VERSION ""

NS_ :

BS_:

BU_: PTECU FECU RECO MECU PC_Tool

BA_DEF_ "VFrameFormat" ENUM "StandardCAN","StandardCAN_FD";
BA_DEF_ BO_ "CAN_FD_BRS" ENUM "0","1";
VAL_ 1808 Engine_State 0 "Desligado" 1 "Partida" 2 "Funcionando" 3 "Falha";

// --------------------------- MECU ---------------------------
BO_ 272 MECU_ReqCuttingBrake: 1 MECU
 SG_ CuttingBreakAtivado : 0|1@1+ (1,0) [0|1] "bool" RECO

BO_ 273 MECU_Status_Seguranca: 1 MECU
 SG_ ChaveGeral_Ativada : 0|1@1+ (1,0) [0|1] "bool" PTECU,FECU,RECO,PC_Tool
 SG_ FarolLigado : 1|1@1+ (1,0) [0|1] "bool" PTECU,FECU,RECO,PC_Tool

BO_ 1856 MECU_Diag_Response: 32 MECU
 SG_ FW_Major_MECU : 0|8@1+ (1,0) [0|255] "" PC_Tool
 SG_ FW_Minor_MECU : 8|8@1+ (1,0) [0|255] "" PC_Tool
 SG_ FW_Patch_MECU : 16|8@1+ (1,0) [0|255] "" PC_Tool
 SG_ Uptime_MECU : 24|32@1+ (1,0) [0|4294967295] "s" PC_Tool

// --------------------------- PTECU ---------------------------
BO_ 32 PTECU_Dados_Motor: 4 PTECU
 SG_ RPM : 0|16@1+ (1,0) [0|6000] "rpm" MECU
 SG_ Vel_Eixo_Traseiro : 16|16@1+ (0.1,0) [0|120] "km/h" MECU

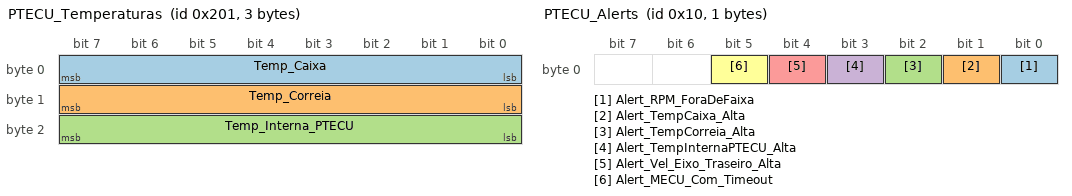
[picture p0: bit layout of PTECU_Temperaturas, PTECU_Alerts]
BO_ 513 PTECU_Temperaturas: 3 PTECU
 SG_ Temp_Caixa : 0|8@1- (1,-40) [-40|500] "C" MECU
 SG_ Temp_Correia : 8|8@1- (1,-40) [-40|500] "C" MECU
 SG_ Temp_Interna_PTECU : 16|8@1- (1,-40) [-40|125] "C" MECU

BO_ 528 PTECU_Sensores_CVT: 4 PTECU
 SG_ Lum_Entrada_Ar_CVT : 0|16@1+ (1,0) [0|65535] "count" MECU
 SG_ Lum_Dia : 16|16@1+ (1,0) [0|65535] "count" MECU

BO_ 529 PTECU_Status_Transmissao: 1 PTECU
 SG_ MarchaRe_Ativada : 0|1@1+ (1,0) [0|1] "bool" MECU,RECO

BO_ 16 PTECU_Alerts: 1 PTECU
 SG_ Alert_RPM_ForaDeFaixa : 0|1@1+ (1,0) [0|1] "bool" MECU
 SG_ Alert_TempCaixa_Alta : 1|1@1+ (1,0) [0|1] "bool" MECU
 SG_ Alert_TempCorreia_Alta : 2|1@1+ (1,0) [0|1] "bool" MECU
 SG_ Alert_TempInternaPTECU_Alta : 3|1@1+ (1,0) [0|1] "bool" MECU
 SG_ Alert_Vel_Eixo_Traseiro_Alta : 4|1@1+ (1,0) [0|1] "bool" MECU
 SG_ Alert_MECU_Com_Timeout : 5|1@1+ (1,0) [0|1] "bool" MECU

BO_ 1808 PTECU_Diag_Response: 32 PTECU
 SG_ FW_Major : 0|8@1+ (1,0) [0|255] "" PC_Tool
 SG_ FW_Minor : 8|8@1+ (1,0) [0|255] "" PC_Tool
 SG_ FW_Patch : 16|8@1+ (1,0) [0|255] "" PC_Tool
 SG_ Uptime_PTECU : 24|32@1+ (1,0) [0|4294967295] "s" PC_Tool
 SG_ Raw_ADC_Temp_Caixa : 56|16@1+ (1,0) [0|65535] "counts" PC_Tool
 SG_ Raw_ADC_Temp_Correia : 72|16@1+ (1,0) [0|65535] "counts" PC_Tool
 SG_ Engine_State : 88|8@1+ (1,0) [0|10] "" PC_Tool

// --------------------------- FECU ---------------------------
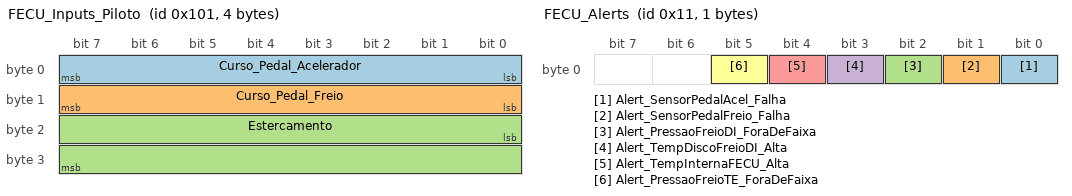
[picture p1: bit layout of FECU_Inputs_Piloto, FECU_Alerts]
BO_ 257 FECU_Inputs_Piloto: 4 FECU
 SG_ Curso_Pedal_Acelerador : 0|8@1+ (0.5,0) [0|100] "%" MECU,PTECU,RECO
 SG_ Curso_Pedal_Freio : 8|8@1+ (0.5,0) [0|100] "%" MECU
 SG_ Estercamento : 16|16@1- (0.1,0) [-90|90] "deg" MECU

BO_ 258 FECU_Dinamica_Veiculo: 16 FECU
 SG_ Vel_Semieixo_DE : 0|16@1+ (0.1,0) [0|120] "km/h" MECU
 SG_ Vel_Semieixo_DD : 16|16@1+ (0.1,0) [0|120] "km/h" MECU
 SG_ Accel_X : 32|16@1- (0.001,0) [-8|8] "g" MECU
 SG_ Accel_Y : 48|16@1- (0.001,0) [-8|8] "g" MECU
 SG_ Vel_Semieixo_TE : 64|16@1+ (0.1,0) [0|120] "km/h" MECU

BO_ 544 FECU_Sistema_Freio_Diant: 2 FECU
 SG_ Pressao_Freio_DI : 0|8@1+ (1,0) [0|100] "bar" MECU
 SG_ Temp_Disco_Freio_DI : 8|8@1- (1,-40) [-40|500] "C" MECU

BO_ 545 FECU_Sistema_Freio_Tras: 2 FECU
 SG_ Pressao_Freio_TE : 0|8@1+ (1,0) [0|100] "bar" MECU
 SG_ Temp_Disco_Freio_TE : 8|8@1- (1,-40) [-40|500] "C" MECU

BO_ 1056 FECU_Status: 1 FECU
 SG_ Temp_Interna_FECU : 0|8@1- (1,-40) [-40|125] "C" MECU

BO_ 17 FECU_Alerts: 1 FECU
 SG_ Alert_SensorPedalAcel_Falha : 0|1@1+ (1,0) [0|1] "bool" MECU
 SG_ Alert_SensorPedalFreio_Falha : 1|1@1+ (1,0) [0|1] "bool" MECU
 SG_ Alert_PressaoFreioDI_ForaDeFaixa : 2|1@1+ (1,0) [0|1] "bool" MECU
 SG_ Alert_TempDiscoFreioDI_Alta : 3|1@1+ (1,0) [0|1] "bool" MECU
 SG_ Alert_TempInternaFECU_Alta : 4|1@1+ (1,0) [0|1] "bool" MECU
 SG_ Alert_PressaoFreioTE_ForaDeFaixa : 5|1@1+ (1,0) [0|1] "bool" MECU

BO_ 1824 FECU_Diag_Response: 32 FECU
 SG_ FW_Major_FECU : 0|8@1+ (1,0) [0|255] "" PC_Tool
 SG_ FW_Minor_FECU : 8|8@1+ (1,0) [0|255] "" PC_Tool
 SG_ FW_Patch_FECU : 16|8@1+ (1,0) [0|255] "" PC_Tool
 SG_ Uptime_FECU : 24|32@1+ (1,0) [0|4294967295] "s" PC_Tool
 SG_ Raw_ADC_Pedal_Acel : 56|16@1+ (1,0) [0|65535] "counts" PC_Tool
 SG_ Raw_ADC_Pedal_Freio : 72|16@1+ (1,0) [0|65535] "counts" PC_Tool
 SG_ Raw_ADC_Estercamento : 88|16@1+ (1,0) [0|65535] "counts" PC_Tool

// --------------------------- RECO ---------------------------
BO_ 514 RECO_Status: 12 RECO
 SG_ Tensao_Bateria : 0|16@1+ (0.01,0) [8|15] "V" MECU
 SG_ Temp_Bateria : 16|8@1- (1,-40) [-40|100] "C" MECU
 SG_ Temp_Disco_Freio_Tras : 24|8@1- (1,-40) [-40|500] "C" MECU
 SG_ Temp_Interna_RECO : 32|8@1- (1,-40) [-40|125] "C" MECU

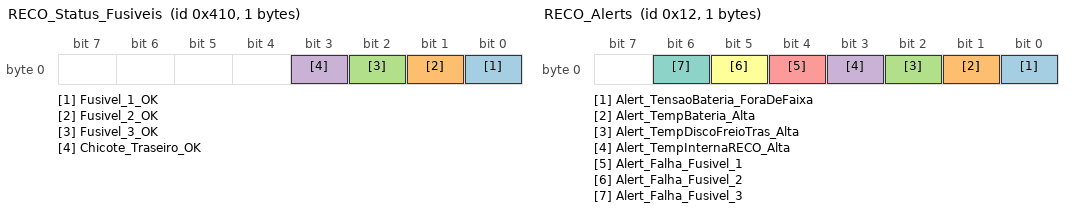
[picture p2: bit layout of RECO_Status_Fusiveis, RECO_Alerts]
BO_ 1040 RECO_Status_Fusiveis: 1 RECO
 SG_ Fusivel_1_OK : 0|1@1+ (1,0) [0|1] "bool" MECU
 SG_ Fusivel_2_OK : 1|1@1+ (1,0) [0|1] "bool" MECU
 SG_ Fusivel_3_OK : 2|1@1+ (1,0) [0|1] "bool" MECU
 SG_ Chicote_Traseiro_OK : 3|1@1+ (1,0) [0|1] "bool" MECU

BO_ 18 RECO_Alerts: 1 RECO
 SG_ Alert_TensaoBateria_ForaDeFaixa : 0|1@1+ (1,0) [0|1] "bool" MECU
 SG_ Alert_TempBateria_Alta : 1|1@1+ (1,0) [0|1] "bool" MECU
 SG_ Alert_TempDiscoFreioTras_Alta : 2|1@1+ (1,0) [0|1] "bool" MECU
 SG_ Alert_TempInternaRECO_Alta : 3|1@1+ (1,0) [0|1] "bool" MECU
 SG_ Alert_Falha_Fusivel_1 : 4|1@1+ (1,0) [0|1] "bool" MECU
 SG_ Alert_Falha_Fusivel_2 : 5|1@1+ (1,0) [0|1] "bool" MECU
 SG_ Alert_Falha_Fusivel_3 : 6|1@1+ (1,0) [0|1] "bool" MECU

BO_ 1840 RECO_Diag_Response: 32 RECO
 SG_ FW_Major_RECO : 0|8@1+ (1,0) [0|255] "" PC_Tool
 SG_ FW_Minor_RECO : 8|8@1+ (1,0) [0|255] "" PC_Tool
 SG_ FW_Patch_RECO : 16|8@1+ (1,0) [0|255] "" PC_Tool
 SG_ Uptime_RECO : 24|32@1+ (1,0) [0|4294967295] "s" PC_Tool

// --------------------------- PC_Tool ---------------------------
BO_ 1791 Global_Diag_Request: 1 PC_Tool
 SG_ Target_Node_ID : 0|8@1+ (1,0) [0|255] "ID_do_No" PTECU,FECU,RECO,MECU

// ---------------------- CAN FD Attributes ----------------------
BA_ "VFrameFormat" BO_ 258 1;
BA_ "CAN_FD_BRS" BO_ 258 1;
BA_ "VFrameFormat" BO_ 514 1;
BA_ "CAN_FD_BRS" BO_ 514 1;
BA_ "VFrameFormat" BO_ 1808 1;
BA_ "CAN_FD_BRS" BO_ 1808 1;
BA_ "VFrameFormat" BO_ 1824 1;
BA_ "CAN_FD_BRS" BO_ 1824 1;
BA_ "VFrameFormat" BO_ 1840 1;
BA_ "CAN_FD_BRS" BO_ 1840 1;
BA_ "VFrameFormat" BO_ 1856 1;
BA_ "CAN_FD_BRS" BO_ 1856 1;
